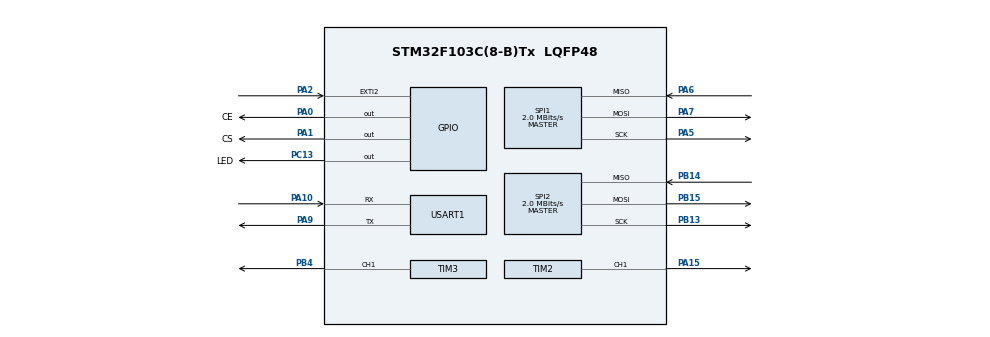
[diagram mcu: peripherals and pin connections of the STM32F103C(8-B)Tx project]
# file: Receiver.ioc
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Mcu.Family=STM32F1
PA2.GPIO_PuPd=GPIO_PULLUP
PA6.Mode=Full_Duplex_Master
SPI1.VirtualType=VM_MASTER
SPI2.VirtualType=VM_MASTER
VP_IWDG_VS_IWDG.Mode=IWDG_Activate
Dma.TIM3_CH4/UP.0.Mode=DMA_CIRCULAR
PB13.Signal=SPI2_SCK
PB15.Signal=SPI2_MOSI
RCC.SYSCLKSource=RCC_SYSCLKSOURCE_PLLCLK
ProjectManager.StackSize=0x400
PD1-OSC_OUT.Signal=RCC_OSC_OUT
NVIC.DMA1_Channel3_IRQn=true\:0\:0\:false\:false\:false\:false\:true
SPI1.Direction=SPI_DIRECTION_2LINES
RCC.HCLKFreq_Value=64000000
RCC.APB2TimFreq_Value=64000000
TIM3.Period=79
SPI1.CalculateBaudRate=2.0 MBits/s
RCC.AHBFreq_Value=64000000
SPI2.BaudRatePrescaler=SPI_BAUDRATEPRESCALER_16
TIM3.Channel-PWM\ Generation1\ CH1=TIM_CHANNEL_1
RCC.PLLMUL=RCC_PLL_MUL8
PA14.Mode=Serial_Wire
PB14.Mode=Full_Duplex_Master
SPI2.CalculateBaudRate=2.0 MBits/s
TIM2.Channel-PWM\ Generation1\ CH1=TIM_CHANNEL_1
SH.S_TIM3_CH1.0=TIM3_CH1,PWM Generation1 CH1
TIM4.Period=999
Mcu.Package=LQFP48
TIM2.Prescaler=250
PA6.Signal=SPI1_MISO
SPI2.Mode=SPI_MODE_MASTER
Dma.TIM3_CH4/UP.0.Priority=DMA_PRIORITY_HIGH
IWDG.Reload=40
PA10.Signal=USART1_RX
PA15.Signal=S_TIM2_CH1_ETR
Dma.TIM3_CH4/UP.0.Direction=DMA_MEMORY_TO_PERIPH
NVIC.EXTI2_IRQn=true\:0\:0\:false\:false\:false\:true\:true
RCC.APB1TimFreq_Value=64000000
SPI2.Direction=SPI_DIRECTION_2LINES
PB13.Mode=Full_Duplex_Master
Dma.Request0=TIM3_CH4/UP
SPI1.BaudRatePrescaler=SPI_BAUDRATEPRESCALER_32
Dma.TIM3_CH4/UP.0.PeriphDataAlignment=DMA_PDATAALIGN_HALFWORD
VP_TIM3_VS_ClockSourceINT.Mode=Internal
PB4.Signal=S_TIM3_CH1
PA5.Mode=Full_Duplex_Master
RCC.PLLSourceVirtual=RCC_PLLSOURCE_HSE
PA7.Mode=Full_Duplex_Master
PD1-OSC_OUT.Mode=HSE-External-Oscillator
PA10.Mode=Asynchronous
PC13-TAMPER-RTC.Signal=GPIO_Output
SPI1.CLKPhase=SPI_PHASE_1EDGE
PD0-OSC_IN.Signal=RCC_OSC_IN
RCC.APB1CLKDivider=RCC_HCLK_DIV2
PA0-WKUP.GPIO_Label=CE
PA0-WKUP.Signal=GPIO_Output
PA13.Signal=SYS_JTMS-SWDIO
PA9.Mode=Asynchronous
ProjectManager.TargetToolchain=STM32CubeIDE
PA9.Signal=USART1_TX
Dma.TIM3_CH4/UP.0.Instance=DMA1_Channel3
RCC.USBFreq_Value=64000000
TIM4.Prescaler=119
PA1.Signal=GPIO_Output
PD0-OSC_IN.Mode=HSE-External-Oscillator
PB14.Signal=SPI2_MISO
PA5.Signal=SPI1_SCK
board=custom
PC13-TAMPER-RTC.GPIO_Label=LED
PB15.Mode=Full_Duplex_Master
RCC.APB2Freq_Value=64000000
VP_TIM2_VS_ClockSourceINT.Mode=Internal
SPI1.Mode=SPI_MODE_MASTER
PA1.GPIO_Label=CS
Dma.TIM3_CH4/UP.0.MemInc=DMA_MINC_ENABLE
TIM2.Period=5099
PA13.Mode=Serial_Wire
Mcu.Name=STM32F103C(8-B)Tx
PA2.Signal=GPXTI2
RCC.SYSCLKFreq_VALUE=64000000
USART1.VirtualMode=VM_ASYNC
SH.S_TIM2_CH1_ETR.0=TIM2_CH1,PWM Generation1 CH1
PA14.Signal=SYS_JTCK-SWCLK
ProjectManager.HeapSize=0x200
Dma.TIM3_CH4/UP.0.MemDataAlignment=DMA_MDATAALIGN_HALFWORD
PA2.GPIO_ModeDefaultEXTI=GPIO_MODE_IT_FALLING
VP_TIM4_VS_ClockSourceINT.Mode=Internal
NVIC.PriorityGroup=NVIC_PRIORITYGROUP_4
IWDG.Prescaler=IWDG_PRESCALER_256
NVIC.TIM4_IRQn=true\:0\:0\:false\:false\:false\:true\:true
RCC.APB1Freq_Value=32000000
Dma.TIM3_CH4/UP.0.PeriphInc=DMA_PINC_DISABLE
PA7.Signal=SPI1_MOSI

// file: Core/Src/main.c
/* USER CODE BEGIN Header */
/**
  ******************************************************************************
  * @file           : main.c
  * @brief          : Main program body
  ******************************************************************************
  * @attention
  *
  * <h2><center>&copy; Copyright (c) 2021 STMicroelectronics.
  * All rights reserved.</center></h2>
  *
  * This software component is licensed by ST under BSD 3-Clause license,
  * the "License"; You may not use this file except in compliance with the
  * License. You may obtain a copy of the License at:
  *                        opensource.org/licenses/BSD-3-Clause
  *
  ******************************************************************************
  */
/* USER CODE END Header */
#include "main.h"

/* USER CODE BEGIN Includes */

#include "user-main.h"

/* USER CODE END Includes */

void SystemClock_Config(void);
static void MX_GPIO_Init(void);
static void MX_DMA_Init(void);
static void MX_SPI1_Init(void);
static void MX_USART1_UART_Init(void);
static void MX_TIM3_Init(void);
static void MX_TIM4_Init(void);
static void MX_TIM2_Init(void);
static void MX_IWDG_Init(void);
static void MX_SPI2_Init(void);

int main(void)
{

  /* MCU Configuration--------------------------------------------------------*/

  /* Reset of all peripherals, Initializes the Flash interface and the Systick. */

  LL_APB2_GRP1_EnableClock(LL_APB2_GRP1_PERIPH_AFIO);
  LL_APB1_GRP1_EnableClock(LL_APB1_GRP1_PERIPH_PWR);

  NVIC_SetPriorityGrouping(NVIC_PRIORITYGROUP_4);

  /* System interrupt init*/

  /** NOJTAG: JTAG-DP Disabled and SW-DP Enabled
  */
  LL_GPIO_AF_Remap_SWJ_NOJTAG();

  /* Configure the system clock */
  SystemClock_Config();

  /* Initialize all configured peripherals */
  MX_GPIO_Init();
  MX_DMA_Init();
  MX_SPI1_Init();
  MX_USART1_UART_Init();
  MX_TIM3_Init();
  MX_TIM4_Init();
  MX_TIM2_Init();
  MX_SPI2_Init();
  /* USER CODE BEGIN 2 */

  UserSetup();

    /* USER CODE END 2 */

  /* Infinite loop */
  /* USER CODE BEGIN WHILE */
    while(1){
        UserLoop();
    }
    /* USER CODE END WHILE */
}

void SystemClock_Config(void)
{
  LL_FLASH_SetLatency(LL_FLASH_LATENCY_2);
  while(LL_FLASH_GetLatency()!= LL_FLASH_LATENCY_2)
  {
  }
  LL_RCC_HSE_Enable();

   /* Wait till HSE is ready */
  while(LL_RCC_HSE_IsReady() != 1)
  {

  }
  LL_RCC_LSI_Enable();

   /* Wait till LSI is ready */
  while(LL_RCC_LSI_IsReady() != 1)
  {

  }
  LL_RCC_PLL_ConfigDomain_SYS(LL_RCC_PLLSOURCE_HSE_DIV_1, LL_RCC_PLL_MUL_8);
  LL_RCC_PLL_Enable();

   /* Wait till PLL is ready */
  while(LL_RCC_PLL_IsReady() != 1)
  {

  }
  LL_RCC_SetAHBPrescaler(LL_RCC_SYSCLK_DIV_1);
  LL_RCC_SetAPB1Prescaler(LL_RCC_APB1_DIV_2);
  LL_RCC_SetAPB2Prescaler(LL_RCC_APB2_DIV_1);
  LL_RCC_SetSysClkSource(LL_RCC_SYS_CLKSOURCE_PLL);

   /* Wait till System clock is ready */
  while(LL_RCC_GetSysClkSource() != LL_RCC_SYS_CLKSOURCE_STATUS_PLL)
  {

  }
  LL_Init1msTick(64000000);
  LL_SetSystemCoreClock(64000000);
}

static void MX_IWDG_Init(void)
{

  LL_IWDG_Enable(IWDG);
  LL_IWDG_EnableWriteAccess(IWDG);
  LL_IWDG_SetPrescaler(IWDG, LL_IWDG_PRESCALER_256);
  LL_IWDG_SetReloadCounter(IWDG, 400);
  while (LL_IWDG_IsReady(IWDG) != 1)
  {
  }

  LL_IWDG_ReloadCounter(IWDG);

}

static void MX_SPI1_Init(void)
{

  LL_SPI_InitTypeDef SPI_InitStruct = {0};

  LL_GPIO_InitTypeDef GPIO_InitStruct = {0};

  /* Peripheral clock enable */
  LL_APB2_GRP1_EnableClock(LL_APB2_GRP1_PERIPH_SPI1);

  LL_APB2_GRP1_EnableClock(LL_APB2_GRP1_PERIPH_GPIOA);
  /**SPI1 GPIO Configuration
  PA5   ------> SPI1_SCK
  PA6   ------> SPI1_MISO
  PA7   ------> SPI1_MOSI
  */
  GPIO_InitStruct.Pin = LL_GPIO_PIN_5|LL_GPIO_PIN_7;
  GPIO_InitStruct.Mode = LL_GPIO_MODE_ALTERNATE;
  GPIO_InitStruct.Speed = LL_GPIO_SPEED_FREQ_HIGH;
  GPIO_InitStruct.OutputType = LL_GPIO_OUTPUT_PUSHPULL;
  LL_GPIO_Init(GPIOA, &GPIO_InitStruct);

  GPIO_InitStruct.Pin = LL_GPIO_PIN_6;
  GPIO_InitStruct.Mode = LL_GPIO_MODE_FLOATING;
  LL_GPIO_Init(GPIOA, &GPIO_InitStruct);

  /* SPI1 parameter configuration*/
  SPI_InitStruct.TransferDirection = LL_SPI_FULL_DUPLEX;
  SPI_InitStruct.Mode = LL_SPI_MODE_MASTER;
  SPI_InitStruct.DataWidth = LL_SPI_DATAWIDTH_8BIT;
  SPI_InitStruct.ClockPolarity = LL_SPI_POLARITY_LOW;
  SPI_InitStruct.ClockPhase = LL_SPI_PHASE_1EDGE;
  SPI_InitStruct.NSS = LL_SPI_NSS_SOFT;
  SPI_InitStruct.BaudRate = LL_SPI_BAUDRATEPRESCALER_DIV32;
  SPI_InitStruct.BitOrder = LL_SPI_MSB_FIRST;
  SPI_InitStruct.CRCCalculation = LL_SPI_CRCCALCULATION_DISABLE;
  SPI_InitStruct.CRCPoly = 10;
  LL_SPI_Init(SPI1, &SPI_InitStruct);

}

static void MX_SPI2_Init(void)
{

  LL_SPI_InitTypeDef SPI_InitStruct = {0};

  LL_GPIO_InitTypeDef GPIO_InitStruct = {0};

  /* Peripheral clock enable */
  LL_APB1_GRP1_EnableClock(LL_APB1_GRP1_PERIPH_SPI2);

  LL_APB2_GRP1_EnableClock(LL_APB2_GRP1_PERIPH_GPIOB);
  /**SPI2 GPIO Configuration
  PB13   ------> SPI2_SCK
  PB14   ------> SPI2_MISO
  PB15   ------> SPI2_MOSI
  */
  GPIO_InitStruct.Pin = LL_GPIO_PIN_13|LL_GPIO_PIN_15;
  GPIO_InitStruct.Mode = LL_GPIO_MODE_ALTERNATE;
  GPIO_InitStruct.Speed = LL_GPIO_SPEED_FREQ_HIGH;
  GPIO_InitStruct.OutputType = LL_GPIO_OUTPUT_PUSHPULL;
  LL_GPIO_Init(GPIOB, &GPIO_InitStruct);

  GPIO_InitStruct.Pin = LL_GPIO_PIN_14;
  GPIO_InitStruct.Mode = LL_GPIO_MODE_FLOATING;
  LL_GPIO_Init(GPIOB, &GPIO_InitStruct);

  /* SPI2 parameter configuration*/
  SPI_InitStruct.TransferDirection = LL_SPI_FULL_DUPLEX;
  SPI_InitStruct.Mode = LL_SPI_MODE_MASTER;
  SPI_InitStruct.DataWidth = LL_SPI_DATAWIDTH_8BIT;
  SPI_InitStruct.ClockPolarity = LL_SPI_POLARITY_LOW;
  SPI_InitStruct.ClockPhase = LL_SPI_PHASE_1EDGE;
  SPI_InitStruct.NSS = LL_SPI_NSS_SOFT;
  SPI_InitStruct.BaudRate = LL_SPI_BAUDRATEPRESCALER_DIV16;
  SPI_InitStruct.BitOrder = LL_SPI_MSB_FIRST;
  SPI_InitStruct.CRCCalculation = LL_SPI_CRCCALCULATION_DISABLE;
  SPI_InitStruct.CRCPoly = 10;
  LL_SPI_Init(SPI2, &SPI_InitStruct);

}

static void MX_TIM2_Init(void)
{

  LL_TIM_InitTypeDef TIM_InitStruct = {0};
  LL_TIM_OC_InitTypeDef TIM_OC_InitStruct = {0};

  LL_GPIO_InitTypeDef GPIO_InitStruct = {0};

  /* Peripheral clock enable */
  LL_APB1_GRP1_EnableClock(LL_APB1_GRP1_PERIPH_TIM2);

  TIM_InitStruct.Prescaler = 250;
  TIM_InitStruct.CounterMode = LL_TIM_COUNTERMODE_UP;
  TIM_InitStruct.Autoreload = 5099;
  TIM_InitStruct.ClockDivision = LL_TIM_CLOCKDIVISION_DIV1;
  LL_TIM_Init(TIM2, &TIM_InitStruct);
  LL_TIM_DisableARRPreload(TIM2);
  LL_TIM_SetClockSource(TIM2, LL_TIM_CLOCKSOURCE_INTERNAL);
  LL_TIM_OC_EnablePreload(TIM2, LL_TIM_CHANNEL_CH1);
  TIM_OC_InitStruct.OCMode = LL_TIM_OCMODE_PWM1;
  TIM_OC_InitStruct.OCState = LL_TIM_OCSTATE_DISABLE;
  TIM_OC_InitStruct.OCNState = LL_TIM_OCSTATE_DISABLE;
  TIM_OC_InitStruct.CompareValue = 0;
  TIM_OC_InitStruct.OCPolarity = LL_TIM_OCPOLARITY_HIGH;
  LL_TIM_OC_Init(TIM2, LL_TIM_CHANNEL_CH1, &TIM_OC_InitStruct);
  LL_TIM_OC_DisableFast(TIM2, LL_TIM_CHANNEL_CH1);
  LL_TIM_SetTriggerOutput(TIM2, LL_TIM_TRGO_RESET);
  LL_TIM_DisableMasterSlaveMode(TIM2);
  LL_APB2_GRP1_EnableClock(LL_APB2_GRP1_PERIPH_GPIOA);
  /**TIM2 GPIO Configuration
  PA15   ------> TIM2_CH1
  */
  GPIO_InitStruct.Pin = LL_GPIO_PIN_15;
  GPIO_InitStruct.Mode = LL_GPIO_MODE_ALTERNATE;
  GPIO_InitStruct.Speed = LL_GPIO_SPEED_FREQ_LOW;
  GPIO_InitStruct.OutputType = LL_GPIO_OUTPUT_PUSHPULL;
  LL_GPIO_Init(GPIOA, &GPIO_InitStruct);

  LL_GPIO_AF_RemapPartial1_TIM2();

}

static void MX_TIM3_Init(void)
{

  LL_TIM_InitTypeDef TIM_InitStruct = {0};
  LL_TIM_OC_InitTypeDef TIM_OC_InitStruct = {0};

  LL_GPIO_InitTypeDef GPIO_InitStruct = {0};

  /* Peripheral clock enable */
  LL_APB1_GRP1_EnableClock(LL_APB1_GRP1_PERIPH_TIM3);

  /* TIM3 DMA Init */

  /* TIM3_CH4_UP Init */
  LL_DMA_SetDataTransferDirection(DMA1, LL_DMA_CHANNEL_3, LL_DMA_DIRECTION_MEMORY_TO_PERIPH);

  LL_DMA_SetChannelPriorityLevel(DMA1, LL_DMA_CHANNEL_3, LL_DMA_PRIORITY_HIGH);

  LL_DMA_SetMode(DMA1, LL_DMA_CHANNEL_3, LL_DMA_MODE_CIRCULAR);

  LL_DMA_SetPeriphIncMode(DMA1, LL_DMA_CHANNEL_3, LL_DMA_PERIPH_NOINCREMENT);

  LL_DMA_SetMemoryIncMode(DMA1, LL_DMA_CHANNEL_3, LL_DMA_MEMORY_INCREMENT);

  LL_DMA_SetPeriphSize(DMA1, LL_DMA_CHANNEL_3, LL_DMA_PDATAALIGN_HALFWORD);

  LL_DMA_SetMemorySize(DMA1, LL_DMA_CHANNEL_3, LL_DMA_MDATAALIGN_HALFWORD);

  TIM_InitStruct.Prescaler = 0;
  TIM_InitStruct.CounterMode = LL_TIM_COUNTERMODE_UP;
  TIM_InitStruct.Autoreload = 79;
  TIM_InitStruct.ClockDivision = LL_TIM_CLOCKDIVISION_DIV1;
  LL_TIM_Init(TIM3, &TIM_InitStruct);
  LL_TIM_DisableARRPreload(TIM3);
  LL_TIM_SetClockSource(TIM3, LL_TIM_CLOCKSOURCE_INTERNAL);
  LL_TIM_OC_EnablePreload(TIM3, LL_TIM_CHANNEL_CH1);
  TIM_OC_InitStruct.OCMode = LL_TIM_OCMODE_PWM1;
  TIM_OC_InitStruct.OCState = LL_TIM_OCSTATE_DISABLE;
  TIM_OC_InitStruct.OCNState = LL_TIM_OCSTATE_DISABLE;
  TIM_OC_InitStruct.CompareValue = 0;
  TIM_OC_InitStruct.OCPolarity = LL_TIM_OCPOLARITY_HIGH;
  LL_TIM_OC_Init(TIM3, LL_TIM_CHANNEL_CH1, &TIM_OC_InitStruct);
  LL_TIM_OC_DisableFast(TIM3, LL_TIM_CHANNEL_CH1);
  LL_TIM_SetTriggerOutput(TIM3, LL_TIM_TRGO_RESET);
  LL_TIM_DisableMasterSlaveMode(TIM3);
  LL_APB2_GRP1_EnableClock(LL_APB2_GRP1_PERIPH_GPIOB);
  /**TIM3 GPIO Configuration
  PB4   ------> TIM3_CH1
  */
  GPIO_InitStruct.Pin = LL_GPIO_PIN_4;
  GPIO_InitStruct.Mode = LL_GPIO_MODE_ALTERNATE;
  GPIO_InitStruct.Speed = LL_GPIO_SPEED_FREQ_LOW;
  GPIO_InitStruct.OutputType = LL_GPIO_OUTPUT_PUSHPULL;
  LL_GPIO_Init(GPIOB, &GPIO_InitStruct);

  LL_GPIO_AF_RemapPartial_TIM3();

}

static void MX_TIM4_Init(void)
{

  LL_TIM_InitTypeDef TIM_InitStruct = {0};

  /* Peripheral clock enable */
  LL_APB1_GRP1_EnableClock(LL_APB1_GRP1_PERIPH_TIM4);

  /* TIM4 interrupt Init */
  NVIC_SetPriority(TIM4_IRQn, NVIC_EncodePriority(NVIC_GetPriorityGrouping(),0, 0));
  NVIC_EnableIRQ(TIM4_IRQn);

  TIM_InitStruct.Prescaler = 119;
  TIM_InitStruct.CounterMode = LL_TIM_COUNTERMODE_UP;
  TIM_InitStruct.Autoreload = 999;
  TIM_InitStruct.ClockDivision = LL_TIM_CLOCKDIVISION_DIV1;
  LL_TIM_Init(TIM4, &TIM_InitStruct);
  LL_TIM_DisableARRPreload(TIM4);
  LL_TIM_SetClockSource(TIM4, LL_TIM_CLOCKSOURCE_INTERNAL);
  LL_TIM_SetTriggerOutput(TIM4, LL_TIM_TRGO_RESET);
  LL_TIM_DisableMasterSlaveMode(TIM4);

}

static void MX_USART1_UART_Init(void)
{

  LL_USART_InitTypeDef USART_InitStruct = {0};

  LL_GPIO_InitTypeDef GPIO_InitStruct = {0};

  /* Peripheral clock enable */
  LL_APB2_GRP1_EnableClock(LL_APB2_GRP1_PERIPH_USART1);

  LL_APB2_GRP1_EnableClock(LL_APB2_GRP1_PERIPH_GPIOA);
  /**USART1 GPIO Configuration
  PA9   ------> USART1_TX
  PA10   ------> USART1_RX
  */
  GPIO_InitStruct.Pin = LL_GPIO_PIN_9;
  GPIO_InitStruct.Mode = LL_GPIO_MODE_ALTERNATE;
  GPIO_InitStruct.Speed = LL_GPIO_SPEED_FREQ_HIGH;
  GPIO_InitStruct.OutputType = LL_GPIO_OUTPUT_PUSHPULL;
  LL_GPIO_Init(GPIOA, &GPIO_InitStruct);

  GPIO_InitStruct.Pin = LL_GPIO_PIN_10;
  GPIO_InitStruct.Mode = LL_GPIO_MODE_FLOATING;
  LL_GPIO_Init(GPIOA, &GPIO_InitStruct);

  USART_InitStruct.BaudRate = 115200;
  USART_InitStruct.DataWidth = LL_USART_DATAWIDTH_8B;
  USART_InitStruct.StopBits = LL_USART_STOPBITS_1;
  USART_InitStruct.Parity = LL_USART_PARITY_NONE;
  USART_InitStruct.TransferDirection = LL_USART_DIRECTION_TX_RX;
  USART_InitStruct.HardwareFlowControl = LL_USART_HWCONTROL_NONE;
  USART_InitStruct.OverSampling = LL_USART_OVERSAMPLING_16;
  LL_USART_Init(USART1, &USART_InitStruct);
  LL_USART_ConfigAsyncMode(USART1);
  LL_USART_Enable(USART1);

}

static void MX_DMA_Init(void)
{

  /* Init with LL driver */
  /* DMA controller clock enable */
  LL_AHB1_GRP1_EnableClock(LL_AHB1_GRP1_PERIPH_DMA1);

  /* DMA interrupt init */
  /* DMA1_Channel3_IRQn interrupt configuration */
  NVIC_SetPriority(DMA1_Channel3_IRQn, NVIC_EncodePriority(NVIC_GetPriorityGrouping(),0, 0));
  NVIC_EnableIRQ(DMA1_Channel3_IRQn);

}

static void MX_GPIO_Init(void)
{
  LL_EXTI_InitTypeDef EXTI_InitStruct = {0};
  LL_GPIO_InitTypeDef GPIO_InitStruct = {0};

  /* GPIO Ports Clock Enable */
  LL_APB2_GRP1_EnableClock(LL_APB2_GRP1_PERIPH_GPIOC);
  LL_APB2_GRP1_EnableClock(LL_APB2_GRP1_PERIPH_GPIOD);
  LL_APB2_GRP1_EnableClock(LL_APB2_GRP1_PERIPH_GPIOA);
  LL_APB2_GRP1_EnableClock(LL_APB2_GRP1_PERIPH_GPIOB);

  /**/
  LL_GPIO_ResetOutputPin(LED_GPIO_Port, LED_Pin);

  /**/
  LL_GPIO_ResetOutputPin(GPIOA, CE_Pin|CS_Pin);

  /**/
  GPIO_InitStruct.Pin = LED_Pin;
  GPIO_InitStruct.Mode = LL_GPIO_MODE_OUTPUT;
  GPIO_InitStruct.Speed = LL_GPIO_SPEED_FREQ_LOW;
  GPIO_InitStruct.OutputType = LL_GPIO_OUTPUT_PUSHPULL;
  LL_GPIO_Init(LED_GPIO_Port, &GPIO_InitStruct);

  /**/
  GPIO_InitStruct.Pin = CE_Pin|CS_Pin;
  GPIO_InitStruct.Mode = LL_GPIO_MODE_OUTPUT;
  GPIO_InitStruct.Speed = LL_GPIO_SPEED_FREQ_LOW;
  GPIO_InitStruct.OutputType = LL_GPIO_OUTPUT_PUSHPULL;
  LL_GPIO_Init(GPIOA, &GPIO_InitStruct);

  /**/
  LL_GPIO_AF_SetEXTISource(LL_GPIO_AF_EXTI_PORTA, LL_GPIO_AF_EXTI_LINE2);

  /**/
  EXTI_InitStruct.Line_0_31 = LL_EXTI_LINE_2;
  EXTI_InitStruct.LineCommand = ENABLE;
  EXTI_InitStruct.Mode = LL_EXTI_MODE_IT;
  EXTI_InitStruct.Trigger = LL_EXTI_TRIGGER_FALLING;
  LL_EXTI_Init(&EXTI_InitStruct);

  /**/
  LL_GPIO_SetPinPull(GPIOA, LL_GPIO_PIN_2, LL_GPIO_PULL_UP);

  /**/
  LL_GPIO_SetPinMode(GPIOA, LL_GPIO_PIN_2, LL_GPIO_MODE_INPUT);

  /* EXTI interrupt init*/
  NVIC_SetPriority(EXTI2_IRQn, NVIC_EncodePriority(NVIC_GetPriorityGrouping(),0, 0));
  NVIC_DisableIRQ(EXTI2_IRQn);

}

void Error_Handler(void)
{
  __disable_irq();
  while (1)
  {
  }
}

/************************ (C) COPYRIGHT STMicroelectronics *****END OF FILE****/
